# MSP432P401Y register map
Vendor: Texas Instruments; File version: 3.230
Registers are 32-bit, read-write, reset 0x0 unless marked. A register's access mark holds for its fields unless they carry their own. Offsets are from the block's base; [hi:lo] are bit positions.

## DIO
Base 0x40004C00
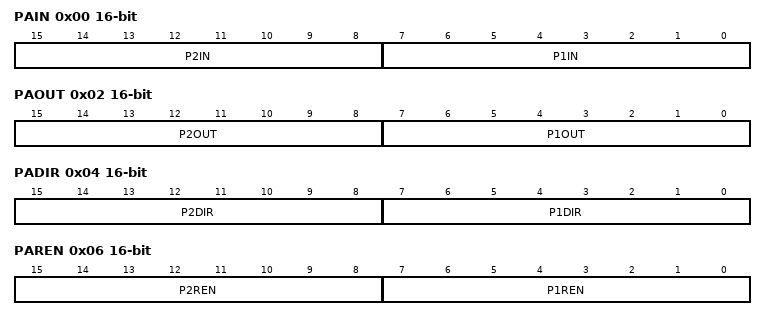
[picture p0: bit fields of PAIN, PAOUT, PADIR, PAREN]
0x00 PAIN 16-bit ro reset not defined — Port A Input
  [15:8] P2IN — Port 2 Input
  [7:0] P1IN — Port 1 Input
0x02 PAOUT 16-bit reset not defined — Port A Output
  [15:8] P2OUT — Port 2 Output
  [7:0] P1OUT — Port 1 Output
0x04 PADIR 16-bit — Port A Direction
  [15:8] P2DIR — Port 2 Direction
  [7:0] P1DIR — Port 1 Direction
0x06 PAREN 16-bit — Port A Resistor Enable
  [15:8] P2REN — Port 2 Resistor Enable
  [7:0] P1REN — Port 1 Resistor Enable
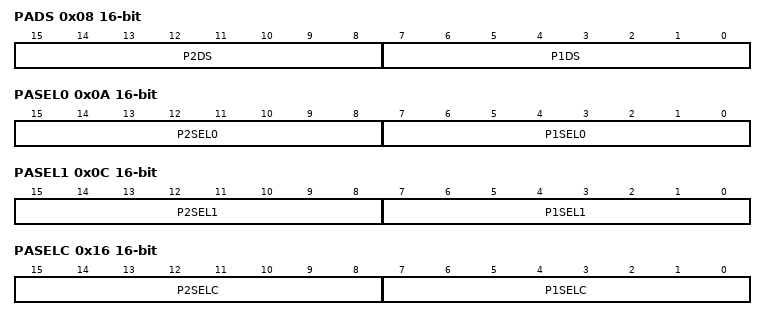
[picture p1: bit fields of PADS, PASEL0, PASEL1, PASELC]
0x08 PADS 16-bit reset not defined — Port A Drive Strength
  [15:8] P2DS — Port 2 Drive Strength
  [7:0] P1DS — Port 1 Drive Strength
0x0A PASEL0 16-bit — Port A Select 0
  [15:8] P2SEL0 — Port 2 Select 0
  [7:0] P1SEL0 — Port 1 Select 0
0x0C PASEL1 16-bit — Port A Select 1
  [15:8] P2SEL1 — Port 2 Select 1
  [7:0] P1SEL1 — Port 1 Select 1
0x0E P1IV 16-bit ro — Port 1 Interrupt Vector Register
  [4:0] P1IV — Port 1 interrupt vector value
    on read: 0=No interrupt pending; 2=Interrupt Source: Port 1.0 interrupt; Interrupt Flag: P1IFG0; Interrupt Priority: Highest; 4=Interrupt Source: Port 1.1 interrupt; Interrupt Flag: P1IFG1; 6=Interrupt Source: Port 1.2 interrupt; Interrupt Flag: P1IFG2; 8=Interrupt Source: Port 1.3 interrupt; Interrupt Flag: P1IFG3; 10=Interrupt Source: Port 1.4 interrupt; Interrupt Flag: P1IFG4; 12=Interrupt Source: Port 1.5 interrupt; Interrupt Flag: P1IFG5; 14=Interrupt Source: Port 1.6 interrupt; Interrupt Flag: P1IFG6; 16=Interrupt Source: Port 1.7 interrupt; Interrupt Flag: P1IFG7; Interrupt Priority: Lowest
0x16 PASELC 16-bit — Port A Complement Select
  [15:8] P2SELC — Port 2 Complement Select
  [7:0] P1SELC — Port 1 Complement Select
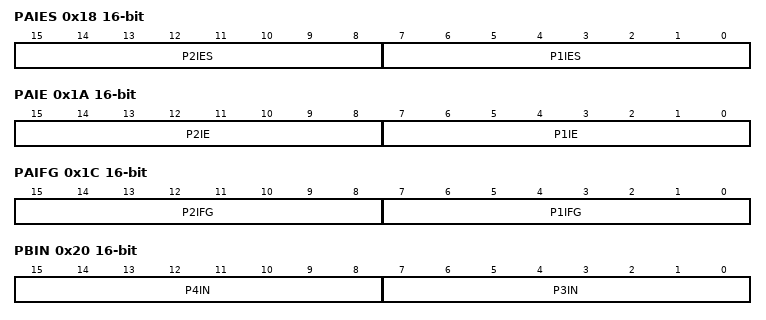
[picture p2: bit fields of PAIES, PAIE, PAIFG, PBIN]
0x18 PAIES 16-bit reset not defined — Port A Interrupt Edge Select
  [15:8] P2IES — Port 2 Interrupt Edge Select
  [7:0] P1IES — Port 1 Interrupt Edge Select
0x1A PAIE 16-bit — Port A Interrupt Enable
  [15:8] P2IE — Port 2 Interrupt Enable
  [7:0] P1IE — Port 1 Interrupt Enable
0x1C PAIFG 16-bit — Port A Interrupt Flag
  [15:8] P2IFG — Port 2 Interrupt Flag
  [7:0] P1IFG — Port 1 Interrupt Flag
0x1E P2IV 16-bit ro reset not defined — Port 2 Interrupt Vector Register
  [4:0] P2IV — Port 2 interrupt vector value
    on read: 0=No interrupt pending; 2=Interrupt Source: Port 2.0 interrupt; Interrupt Flag: P2IFG0; Interrupt Priority: Highest; 4=Interrupt Source: Port 2.1 interrupt; Interrupt Flag: P2IFG1; 6=Interrupt Source: Port 2.2 interrupt; Interrupt Flag: P2IFG2; 8=Interrupt Source: Port 2.3 interrupt; Interrupt Flag: P2IFG3; 10=Interrupt Source: Port 2.4 interrupt; Interrupt Flag: P2IFG4; 12=Interrupt Source: Port 2.5 interrupt; Interrupt Flag: P2IFG5; 14=Interrupt Source: Port 2.6 interrupt; Interrupt Flag: P2IFG6; 16=Interrupt Source: Port 2.7 interrupt; Interrupt Flag: P2IFG7; Interrupt Priority: Lowest
0x20 PBIN 16-bit ro reset not defined — Port B Input
  [15:8] P4IN — Port 4 Input
  [7:0] P3IN — Port 3 Input
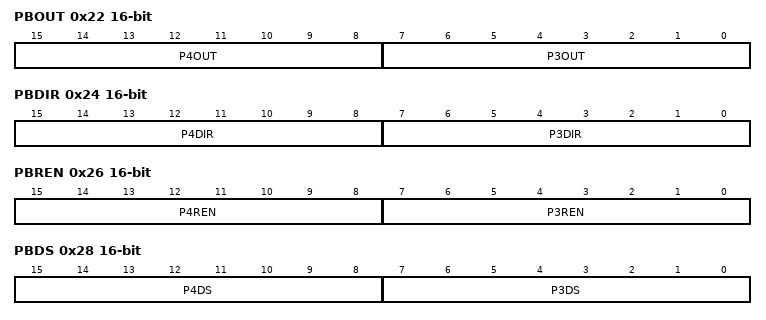
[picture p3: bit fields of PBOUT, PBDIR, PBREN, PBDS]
0x22 PBOUT 16-bit reset not defined — Port B Output
  [15:8] P4OUT — Port 4 Output
  [7:0] P3OUT — Port 3 Output
0x24 PBDIR 16-bit — Port B Direction
  [15:8] P4DIR — Port 4 Direction
  [7:0] P3DIR — Port 3 Direction
0x26 PBREN 16-bit — Port B Resistor Enable
  [15:8] P4REN — Port 4 Resistor Enable
  [7:0] P3REN — Port 3 Resistor Enable
0x28 PBDS 16-bit reset not defined — Port B Drive Strength
  [15:8] P4DS — Port 4 Drive Strength
  [7:0] P3DS — Port 3 Drive Strength
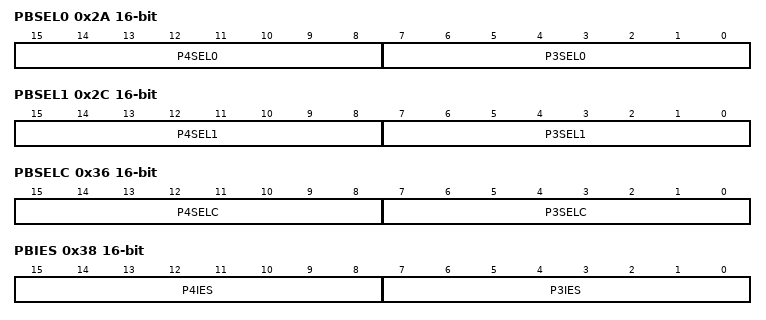
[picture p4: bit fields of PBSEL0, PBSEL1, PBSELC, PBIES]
0x2A PBSEL0 16-bit — Port B Select 0
  [15:8] P4SEL0 — Port 4 Select 0
  [7:0] P3SEL0 — Port 3 Select 0
0x2C PBSEL1 16-bit — Port B Select 1
  [15:8] P4SEL1 — Port 4 Select 1
  [7:0] P3SEL1 — Port 3 Select 1
0x2E P3IV 16-bit ro — Port 3 Interrupt Vector Register
  [4:0] P3IV — Port 3 interrupt vector value
    on read: 0=No interrupt pending; 2=Interrupt Source: Port 3.0 interrupt; Interrupt Flag: P3IFG0; Interrupt Priority: Highest; 4=Interrupt Source: Port 3.1 interrupt; Interrupt Flag: P3IFG1; 6=Interrupt Source: Port 3.2 interrupt; Interrupt Flag: P3IFG2; 8=Interrupt Source: Port 3.3 interrupt; Interrupt Flag: P3IFG3; 10=Interrupt Source: Port 3.4 interrupt; Interrupt Flag: P3IFG4; 12=Interrupt Source: Port 3.5 interrupt; Interrupt Flag: P3IFG5; 14=Interrupt Source: Port 3.6 interrupt; Interrupt Flag: P3IFG6; 16=Interrupt Source: Port 3.7 interrupt; Interrupt Flag: P3IFG7; Interrupt Priority: Lowest
0x36 PBSELC 16-bit — Port B Complement Select
  [15:8] P4SELC — Port 4 Complement Select
  [7:0] P3SELC — Port 3 Complement Select
0x38 PBIES 16-bit reset not defined — Port B Interrupt Edge Select
  [15:8] P4IES — Port 4 Interrupt Edge Select
  [7:0] P3IES — Port 3 Interrupt Edge Select
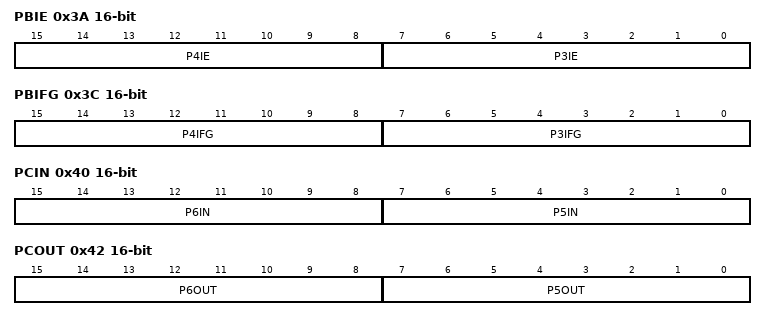
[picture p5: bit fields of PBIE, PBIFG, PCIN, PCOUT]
0x3A PBIE 16-bit — Port B Interrupt Enable
  [15:8] P4IE — Port 4 Interrupt Enable
  [7:0] P3IE — Port 3 Interrupt Enable
0x3C PBIFG 16-bit — Port B Interrupt Flag
  [15:8] P4IFG — Port 4 Interrupt Flag
  [7:0] P3IFG — Port 3 Interrupt Flag
0x3E P4IV 16-bit ro reset not defined — Port 4 Interrupt Vector Register
  [4:0] P4IV — Port 4 interrupt vector value
    on read: 0=No interrupt pending; 2=Interrupt Source: Port 4.0 interrupt; Interrupt Flag: P4IFG0; Interrupt Priority: Highest; 4=Interrupt Source: Port 4.1 interrupt; Interrupt Flag: P4IFG1; 6=Interrupt Source: Port 4.2 interrupt; Interrupt Flag: P4IFG2; 8=Interrupt Source: Port 4.3 interrupt; Interrupt Flag: P4IFG3; 10=Interrupt Source: Port 4.4 interrupt; Interrupt Flag: P4IFG4; 12=Interrupt Source: Port 4.5 interrupt; Interrupt Flag: P4IFG5; 14=Interrupt Source: Port 4.6 interrupt; Interrupt Flag: P4IFG6; 16=Interrupt Source: Port 4.7 interrupt; Interrupt Flag: P4IFG7; Interrupt Priority: Lowest
0x40 PCIN 16-bit ro reset not defined — Port C Input
  [15:8] P6IN — Port 6 Input
  [7:0] P5IN — Port 5 Input
0x42 PCOUT 16-bit reset not defined — Port C Output
  [15:8] P6OUT — Port 6 Output
  [7:0] P5OUT — Port 5 Output
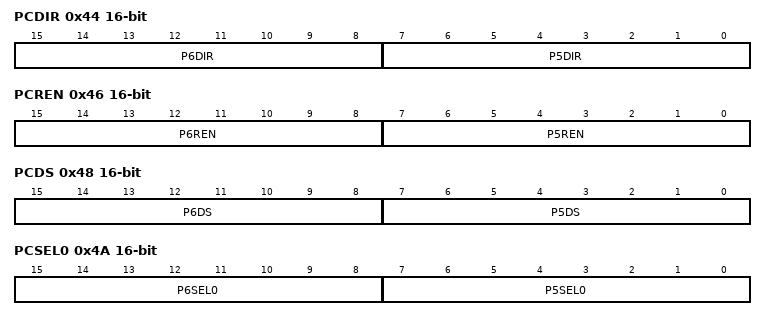
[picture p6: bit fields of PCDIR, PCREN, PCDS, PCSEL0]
0x44 PCDIR 16-bit — Port C Direction
  [15:8] P6DIR — Port 6 Direction
  [7:0] P5DIR — Port 5 Direction
0x46 PCREN 16-bit — Port C Resistor Enable
  [15:8] P6REN — Port 6 Resistor Enable
  [7:0] P5REN — Port 5 Resistor Enable
0x48 PCDS 16-bit reset not defined — Port C Drive Strength
  [15:8] P6DS — Port 6 Drive Strength
  [7:0] P5DS — Port 5 Drive Strength
0x4A PCSEL0 16-bit — Port C Select 0
  [15:8] P6SEL0 — Port 6 Select 0
  [7:0] P5SEL0 — Port 5 Select 0
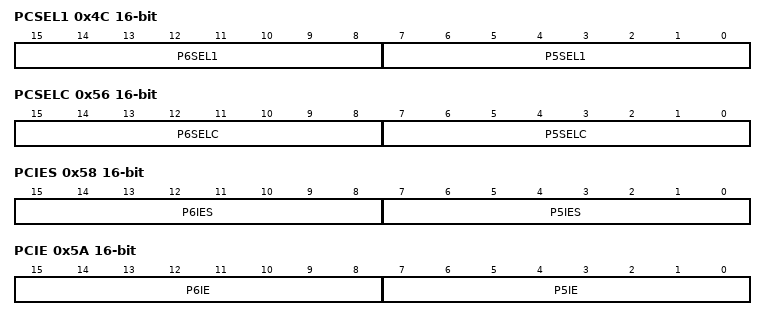
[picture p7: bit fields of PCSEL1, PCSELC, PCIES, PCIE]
0x4C PCSEL1 16-bit — Port C Select 1
  [15:8] P6SEL1 — Port 6 Select 1
  [7:0] P5SEL1 — Port 5 Select 1
0x4E P5IV 16-bit ro — Port 5 Interrupt Vector Register
  [4:0] P5IV — Port 5 interrupt vector value
    on read: 0=No interrupt pending; 2=Interrupt Source: Port 5.0 interrupt; Interrupt Flag: P5IFG0; Interrupt Priority: Highest; 4=Interrupt Source: Port 5.1 interrupt; Interrupt Flag: P5IFG1; 6=Interrupt Source: Port 5.2 interrupt; Interrupt Flag: P5IFG2; 8=Interrupt Source: Port 5.3 interrupt; Interrupt Flag: P5IFG3; 10=Interrupt Source: Port 5.4 interrupt; Interrupt Flag: P5IFG4; 12=Interrupt Source: Port 5.5 interrupt; Interrupt Flag: P5IFG5; 14=Interrupt Source: Port 5.6 interrupt; Interrupt Flag: P5IFG6; 16=Interrupt Source: Port 5.7 interrupt; Interrupt Flag: P5IFG7; Interrupt Priority: Lowest
0x56 PCSELC 16-bit — Port C Complement Select
  [15:8] P6SELC — Port 6 Complement Select
  [7:0] P5SELC — Port 5 Complement Select
0x58 PCIES 16-bit reset not defined — Port C Interrupt Edge Select
  [15:8] P6IES — Port 6 Interrupt Edge Select
  [7:0] P5IES — Port 5 Interrupt Edge Select
0x5A PCIE 16-bit — Port C Interrupt Enable
  [15:8] P6IE — Port 6 Interrupt Enable
  [7:0] P5IE — Port 5 Interrupt Enable
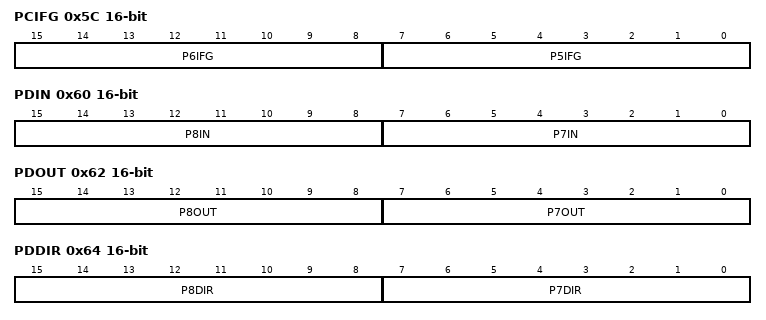
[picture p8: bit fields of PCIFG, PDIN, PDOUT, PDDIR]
0x5C PCIFG 16-bit — Port C Interrupt Flag
  [15:8] P6IFG — Port 6 Interrupt Flag
  [7:0] P5IFG — Port 5 Interrupt Flag
0x5E P6IV 16-bit ro reset not defined — Port 6 Interrupt Vector Register
  [4:0] P6IV — Port 6 interrupt vector value
    on read: 0=No interrupt pending; 2=Interrupt Source: Port 6.0 interrupt; Interrupt Flag: P6IFG0; Interrupt Priority: Highest; 4=Interrupt Source: Port 6.1 interrupt; Interrupt Flag: P6IFG1; 6=Interrupt Source: Port 6.2 interrupt; Interrupt Flag: P6IFG2; 8=Interrupt Source: Port 6.3 interrupt; Interrupt Flag: P6IFG3; 10=Interrupt Source: Port 6.4 interrupt; Interrupt Flag: P6IFG4; 12=Interrupt Source: Port 6.5 interrupt; Interrupt Flag: P6IFG5; 14=Interrupt Source: Port 6.6 interrupt; Interrupt Flag: P6IFG6; 16=Interrupt Source: Port 6.7 interrupt; Interrupt Flag: P6IFG7; Interrupt Priority: Lowest
0x60 PDIN 16-bit ro reset not defined — Port D Input
  [15:8] P8IN — Port 8 Input
  [7:0] P7IN — Port 7 Input
0x62 PDOUT 16-bit reset not defined — Port D Output
  [15:8] P8OUT — Port 8 Output
  [7:0] P7OUT — Port 7 Output
0x64 PDDIR 16-bit — Port D Direction
  [15:8] P8DIR — Port 8 Direction
  [7:0] P7DIR — Port 7 Direction
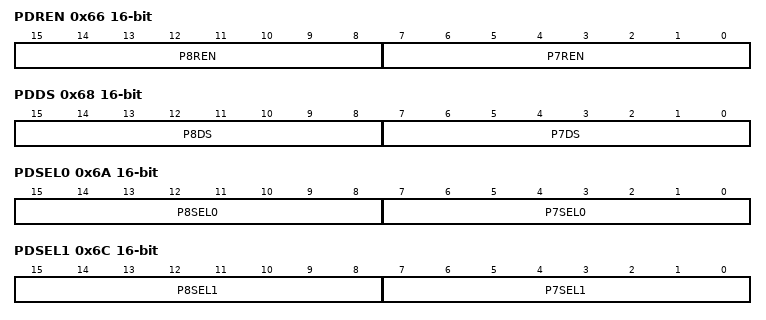
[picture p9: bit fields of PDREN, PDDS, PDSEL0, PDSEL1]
0x66 PDREN 16-bit — Port D Resistor Enable
  [15:8] P8REN — Port 8 Resistor Enable
  [7:0] P7REN — Port 7 Resistor Enable
0x68 PDDS 16-bit reset not defined — Port D Drive Strength
  [15:8] P8DS — Port 8 Drive Strength
  [7:0] P7DS — Port 7 Drive Strength
0x6A PDSEL0 16-bit — Port D Select 0
  [15:8] P8SEL0 — Port 8 Select 0
  [7:0] P7SEL0 — Port 7 Select 0
0x6C PDSEL1 16-bit — Port D Select 1
  [15:8] P8SEL1 — Port 8 Select 1
  [7:0] P7SEL1 — Port 7 Select 1
0x6E P7IV 16-bit ro — Port 7 Interrupt Vector Register
  [4:0] P7IV — Port 7 interrupt vector value
    on read: 0=No interrupt pending; 2=Interrupt Source: Port 7.0 interrupt; Interrupt Flag: P7IFG0; Interrupt Priority: Highest; 4=Interrupt Source: Port 7.1 interrupt; Interrupt Flag: P7IFG1; 6=Interrupt Source: Port 7.2 interrupt; Interrupt Flag: P7IFG2; 8=Interrupt Source: Port 7.3 interrupt; Interrupt Flag: P7IFG3; 10=Interrupt Source: Port 7.4 interrupt; Interrupt Flag: P7IFG4; 12=Interrupt Source: Port 7.5 interrupt; Interrupt Flag: P7IFG5; 14=Interrupt Source: Port 7.6 interrupt; Interrupt Flag: P7IFG6; 16=Interrupt Source: Port 7.7 interrupt; Interrupt Flag: P7IFG7; Interrupt Priority: Lowest
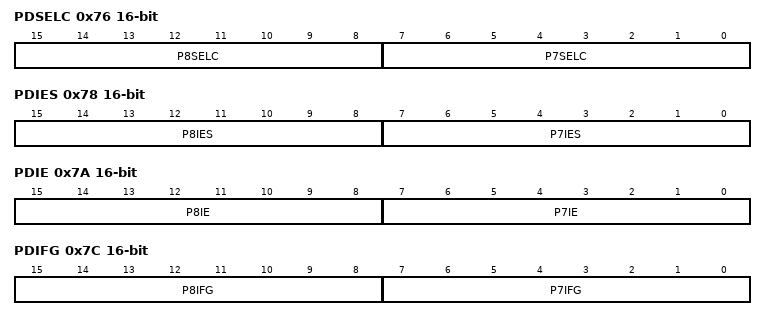
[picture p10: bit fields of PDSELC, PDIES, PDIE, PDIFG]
0x76 PDSELC 16-bit — Port D Complement Select
  [15:8] P8SELC — Port 8 Complement Select
  [7:0] P7SELC — Port 7 Complement Select
0x78 PDIES 16-bit reset not defined — Port D Interrupt Edge Select
  [15:8] P8IES — Port 8 Interrupt Edge Select
  [7:0] P7IES — Port 7 Interrupt Edge Select
0x7A PDIE 16-bit — Port D Interrupt Enable
  [15:8] P8IE — Port 8 Interrupt Enable
  [7:0] P7IE — Port 7 Interrupt Enable
0x7C PDIFG 16-bit — Port D Interrupt Flag
  [15:8] P8IFG — Port 8 Interrupt Flag
  [7:0] P7IFG — Port 7 Interrupt Flag
0x7E P8IV 16-bit ro reset not defined — Port 8 Interrupt Vector Register
  [4:0] P8IV — Port 8 interrupt vector value
    on read: 0=No interrupt pending; 2=Interrupt Source: Port 8.0 interrupt; Interrupt Flag: P8IFG0; Interrupt Priority: Highest; 4=Interrupt Source: Port 8.1 interrupt; Interrupt Flag: P8IFG1; 6=Interrupt Source: Port 8.2 interrupt; Interrupt Flag: P8IFG2; 8=Interrupt Source: Port 8.3 interrupt; Interrupt Flag: P8IFG3; 10=Interrupt Source: Port 8.4 interrupt; Interrupt Flag: P8IFG4; 12=Interrupt Source: Port 8.5 interrupt; Interrupt Flag: P8IFG5; 14=Interrupt Source: Port 8.6 interrupt; Interrupt Flag: P8IFG6; 16=Interrupt Source: Port 8.7 interrupt; Interrupt Flag: P8IFG7; Interrupt Priority: Lowest
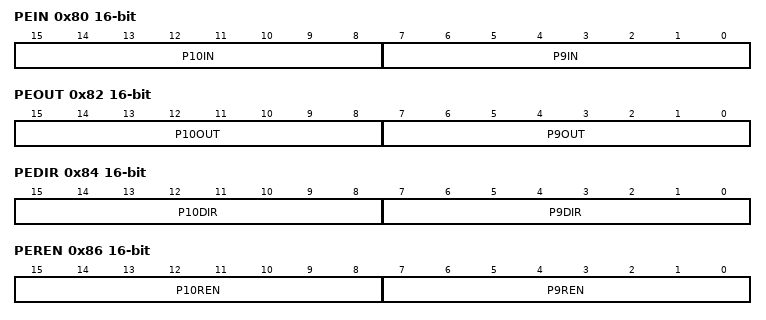
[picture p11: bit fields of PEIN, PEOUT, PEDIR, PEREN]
0x80 PEIN 16-bit ro reset not defined — Port E Input
  [15:8] P10IN — Port 10 Input
  [7:0] P9IN — Port 9 Input
0x82 PEOUT 16-bit reset not defined — Port E Output
  [15:8] P10OUT — Port 10 Output
  [7:0] P9OUT — Port 9 Output
0x84 PEDIR 16-bit — Port E Direction
  [15:8] P10DIR — Port 10 Direction
  [7:0] P9DIR — Port 9 Direction
0x86 PEREN 16-bit — Port E Resistor Enable
  [15:8] P10REN — Port 10 Resistor Enable
  [7:0] P9REN — Port 9 Resistor Enable
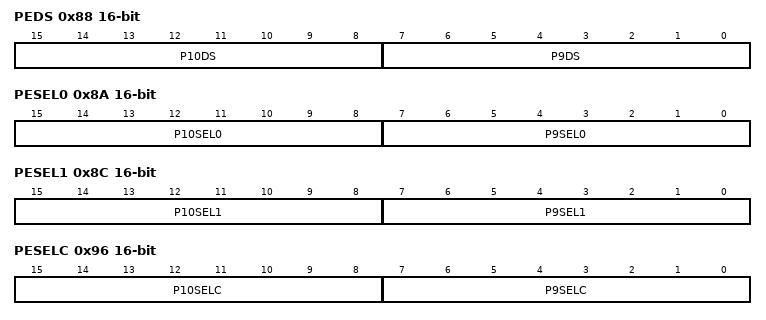
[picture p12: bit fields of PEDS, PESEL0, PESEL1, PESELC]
0x88 PEDS 16-bit reset not defined — Port E Drive Strength
  [15:8] P10DS — Port 10 Drive Strength
  [7:0] P9DS — Port 9 Drive Strength
0x8A PESEL0 16-bit — Port E Select 0
  [15:8] P10SEL0 — Port 10 Select 0
  [7:0] P9SEL0 — Port 9 Select 0
0x8C PESEL1 16-bit — Port E Select 1
  [15:8] P10SEL1 — Port 10 Select 1
  [7:0] P9SEL1 — Port 9 Select 1
0x8E P9IV 16-bit ro — Port 9 Interrupt Vector Register
  [4:0] P9IV — Port 9 interrupt vector value
    on read: 0=No interrupt pending; 2=Interrupt Source: Port 9.0 interrupt; Interrupt Flag: P9IFG0; Interrupt Priority: Highest; 4=Interrupt Source: Port 9.1 interrupt; Interrupt Flag: P9IFG1; 6=Interrupt Source: Port 9.2 interrupt; Interrupt Flag: P9IFG2; 8=Interrupt Source: Port 9.3 interrupt; Interrupt Flag: P9IFG3; 10=Interrupt Source: Port 9.4 interrupt; Interrupt Flag: P9IFG4; 12=Interrupt Source: Port 9.5 interrupt; Interrupt Flag: P9IFG5; 14=Interrupt Source: Port 9.6 interrupt; Interrupt Flag: P9IFG6; 16=Interrupt Source: Port 9.7 interrupt; Interrupt Flag: P9IFG7; Interrupt Priority: Lowest
0x96 PESELC 16-bit — Port E Complement Select
  [15:8] P10SELC — Port 10 Complement Select
  [7:0] P9SELC — Port 9 Complement Select
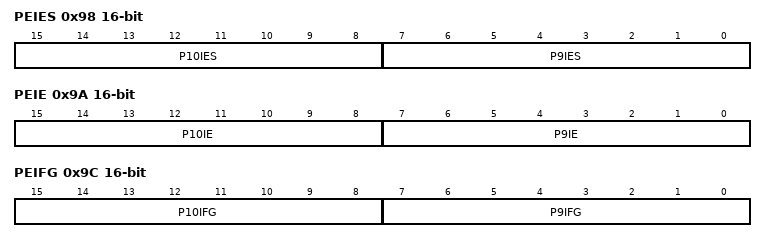
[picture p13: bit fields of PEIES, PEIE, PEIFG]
0x98 PEIES 16-bit reset not defined — Port E Interrupt Edge Select
  [15:8] P10IES — Port 10 Interrupt Edge Select
  [7:0] P9IES — Port 9 Interrupt Edge Select
0x9A PEIE 16-bit — Port E Interrupt Enable
  [15:8] P10IE — Port 10 Interrupt Enable
  [7:0] P9IE — Port 9 Interrupt Enable
0x9C PEIFG 16-bit — Port E Interrupt Flag
  [15:8] P10IFG — Port 10 Interrupt Flag
  [7:0] P9IFG — Port 9 Interrupt Flag
0x9E P10IV 16-bit ro reset not defined — Port 10 Interrupt Vector Register
  [4:0] P10IV — Port 10 interrupt vector value
    on read: 0=No interrupt pending; 2=Interrupt Source: Port 10.0 interrupt; Interrupt Flag: P10IFG0; Interrupt Priority: Highest; 4=Interrupt Source: Port 10.1 interrupt; Interrupt Flag: P10IFG1; 6=Interrupt Source: Port 10.2 interrupt; Interrupt Flag: P10IFG2; 8=Interrupt Source: Port 10.3 interrupt; Interrupt Flag: P10IFG3; 10=Interrupt Source: Port 10.4 interrupt; Interrupt Flag: P10IFG4; 12=Interrupt Source: Port 10.5 interrupt; Interrupt Flag: P10IFG5; 14=Interrupt Source: Port 10.6 interrupt; Interrupt Flag: P10IFG6; 16=Interrupt Source: Port 10.7 interrupt; Interrupt Flag: P10IFG7; Interrupt Priority: Lowest
0x120 PJIN 16-bit ro reset not defined — Port J Input
0x122 PJOUT 16-bit reset not defined — Port J Output
0x124 PJDIR 16-bit — Port J Direction
0x126 PJREN 16-bit — Port J Resistor Enable
0x128 PJDS 16-bit reset not defined — Port J Drive Strength
0x12A PJSEL0 16-bit — Port J Select 0
0x12C PJSEL1 16-bit — Port J Select 1
0x136 PJSELC 16-bit — Port J Complement Select

## Notices in the file
Copyright (C) 2012-2018 Texas Instruments Incorporated - http://www.ti.com
Redistribution and use in source and binary forms, with or without
modification, are permitted provided that the following conditions
are met:
Redistributions of source code must retain the above copyright
notice, this list of conditions and the following disclaimer.
Redistributions in binary form must reproduce the above copyright
notice, this list of conditions and the following disclaimer in the
documentation and/or other materials provided with the
distribution.
Neither the name of Texas Instruments Incorporated nor the names of
its contributors may be used to endorse or promote products derived
from this software without specific prior written permission.
THIS SOFTWARE IS PROVIDED BY THE COPYRIGHT HOLDERS AND CONTRIBUTORS
"AS IS" AND ANY EXPRESS OR IMPLIED WARRANTIES, INCLUDING, BUT NOT
LIMITED TO, THE IMPLIED WARRANTIES OF MERCHANTABILITY AND FITNESS FOR
A PARTICULAR PURPOSE ARE DISCLAIMED. IN NO EVENT SHALL THE COPYRIGHT
OWNER OR CONTRIBUTORS BE LIABLE FOR ANY DIRECT, INDIRECT, INCIDENTAL,
SPECIAL, EXEMPLARY, OR CONSEQUENTIAL DAMAGES (INCLUDING, BUT NOT
LIMITED TO, PROCUREMENT OF SUBSTITUTE GOODS OR SERVICES; LOSS OF USE,
DATA, OR PROFITS; OR BUSINESS INTERRUPTION) HOWEVER CAUSED AND ON ANY
THEORY OF LIABILITY, WHETHER IN CONTRACT, STRICT LIABILITY, OR TORT
(INCLUDING NEGLIGENCE OR OTHERWISE) ARISING IN ANY WAY OUT OF THE USE
OF THIS SOFTWARE, EVEN IF ADVISED OF THE POSSIBILITY OF SUCH DAMAGE.
